# EG32M0x register map
Vendor: EGmicro Ltd.; Series: EG32M0x; File version: 1.0
CPU: CM0 r0p0, little endian, no MPU, no FPU, 3 interrupt priority bits
Registers are 32-bit, read-write, reset 0x0 unless marked. A register's access mark holds for its fields unless they carry their own. Offsets are from the block's base; [hi:lo] are bit positions; lines under a group give offsets from that group; {n}, {i} and the like mark numbered series; 'fields as' and 'values as' point back to an identical list.

## UART0 — UART0 unit
Base 0x40020290
Same registers: UART1 0x400202A0
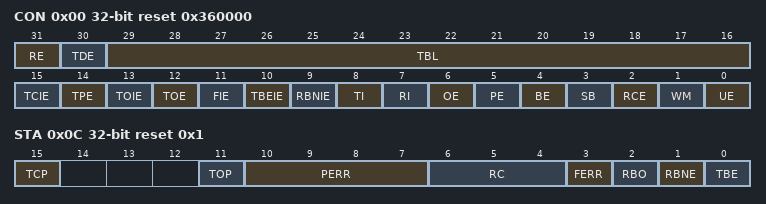
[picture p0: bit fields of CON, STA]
0x00 CON reset 0x360000
  [31] RE — DMA receive request enable configuration
  [30] TDE — DMA send request enable configuration
  [29:16] TBL — Timeout configuration
  [15] TCIE — The UART send completion interrupt was enabled
  [14] TPE — The TX of UART has TMR PWM carrier
  [13] TOIE — TIME OUT Indicates the interrupt enable bit
  [12] TOE — TIME OUT detects the enable bit
  [11] FIE — Frame error interrupt enable bit
  [10] TBEIE — Send buffer air break enable bit
  [9] RBNIE — Receive buffer non - air break enable bit
  [8] TI — Send the output signal to take the inverse selection bit
  [7] RI — Receive the input signal to take the inverse selection bit
  [6] OE — Parity check selection
  [5] PE — Parity check is enabled
  [4] BE — UART transmits 9bit data mode selection bits
  [3] SB — UART stop bit selection
  [2] RCE — Disable the UART receiving function
  [1] WM — UART working mode selection
  [0] UE — The UART module enabled bit
0x04 BAUD reset 0x9C3
  [17:0] BAUD — UART Baud rate control register
0x08 DATA
  [8:0] DATA — UART data register
0x0C STA reset 0x1
  [15] TCP — UART Send completion flag
  [11] TOP — TIME OUT flag bit
  [10:7] PERR — UART Parity check flag bit
  [6:4] RC — The number of cached data received by UART
  [3] FERR — Frame error
  [2] RBO — UART receive cache full flag
  [1] RBNE — Receive buffer non-empty flag
  [0] TBE — UART sends cache empty flag

## TIMER7 — TIMER7 unit
Base 0x40020310
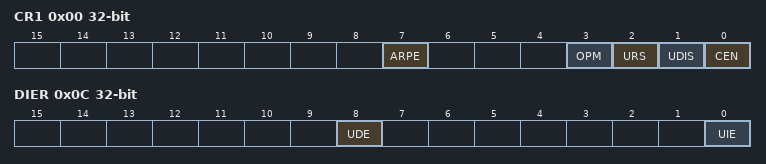
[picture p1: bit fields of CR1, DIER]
0x00 CR1
  [7] ARPE — Automatic reloading preloading allows bits
  [3] OPM — Single pulse mode
  [2] URS — Update request source
  [1] UDIS — Forbid updating
  [0] CEN — Enable counter
0x04 CR2
  [6:4] MMS — Master mode selection
0x0C DIER
  [8] UDE — DMA requests that allow updates
  [0] UIE — Allow update interrupt
0x10 SR
  [0] UIF — Update interrupt flag
0x14 EGR
  [0] UG — Generate update event
0x18 CNT
  [15:0] CNT — Counter value
0x1C PSC
  [15:0] PSC — The value of the pre-divider
0x20 ARR reset 0xFFFF
  [15:0] ARR — The value of automatic reloading

## ADC — ADC unit
Base 0x40020140
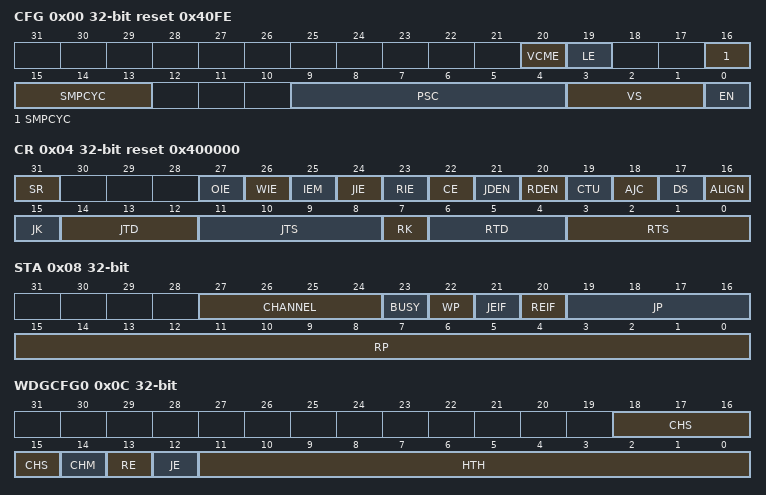
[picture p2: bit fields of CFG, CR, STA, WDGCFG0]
0x00 CFG reset 0x40FE
  [20] VCME — Enable VCM in ADC register
  [19] LE — Internal LDO of ADC module
  [16:13] SMPCYC — The interval between transitions
  [9:4] PSC — ADC predivision
  [3:1] VS — ADC reference voltage selection
  [0] EN — ADC enablement
0x04 CR reset 0x400000
  [31] SR — The software resets the internal state machine of the module
  [27] OIE — Overrun Interrupt enable bit
  [26] WIE — Threshold Watchdog interrupt enable bit
  [25] IEM — A/D interrupt mode bit
  [24] JIE — Injection channel A/D transition interrupt enable bit
  [23] RIE — Rule channel A/D transition interrupt enable bit
  [22] CE — Hardware data calibration enable bit
  [21] JDEN — Injection channel DMA enabled
  [20] RDEN — Enable regular channel DMA
  [19] CTU — Continuous conversion
  [18] AJC — Automatically starts the injection channel group conversion
  [17] DS — Data expansion bit selection
  [16] ALIGN — Data alignment
  [15] JK — The transformation of the injection channel begins
  [14:12] JTD — Delay sampling is triggered outside the injection channel
  [11:8] JTS — Trigger source selection for the injection channel
  [7] RK — The conversion of the regular channel begins
  [6:4] RTD — Delayed sampling is triggered externally by a regular channel
  [3:0] RTS — Trigger source selection for a rule channel
0x08 STA
  [27:24] CHANNEL — Current transfer channel
  [23] BUSY — Busy/idle flag
  [22] WP — Threshold watchdog flag bit
  [21] JEIF — Injection channel A/D conversion end flag bit
  [20] REIF — Rule channel A/D conversion end flag bit
  [19:16] JP — Injection channel conversion complete flag bit
  [15:0] RP — Regular channel conversion complete flag bit
0x0C WDGCFG0
  [18:15] CHS — Watchdog channel selector bit
  [14] CHM — Watchdog channel selection mode
  [13] RE — Turn on the watchdog in the regular aisle
  [12] JE — Enable watchdog on the injection channel
  [11:0] HTH — Watchdog high threshold
0x10 WDGCFG1
  [11:0] LTH — Watchdog low threshold
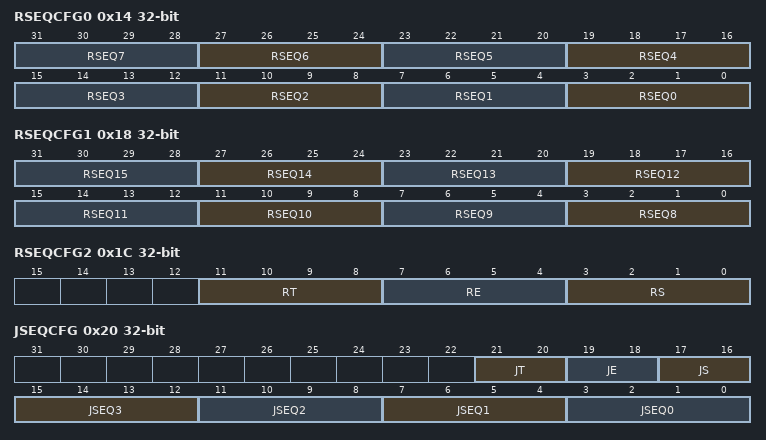
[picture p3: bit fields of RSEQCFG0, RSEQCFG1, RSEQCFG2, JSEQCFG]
0x14 RSEQCFG0
  [4n+3:4n] RSEQ{n} (n=0..7) — Channel configuration for rule sequence index {n}
0x18 RSEQCFG1
  [4n-29:4n-32] RSEQ{n} (n=8..15) — Channel configuration for rule sequence index {n}
0x1C RSEQCFG2
  [11:8] RT — Number of indexes for each conversion triggered by a rule sequence
  [7:4] RE — Regular sequence conversion ends index
  [3:0] RS — Regular sequence converts start index
0x20 JSEQCFG
  [21:20] JT — The number of indexes for each conversion triggered by the injection sequence
  [19:18] JE — The injection sequence converts the end index
  [17:16] JS — The injection sequence converts the star index
  [4n+3:4n] JSEQ{n} (n=0..3) — Channel configuration for injection sequence index {n}
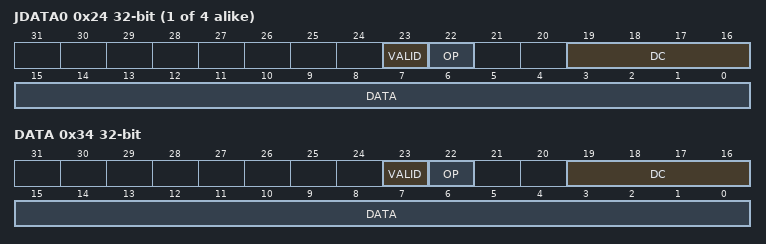
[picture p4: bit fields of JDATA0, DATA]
{0x24+4i} JDATA{i} (i=0..3)
  [23] VALID — DATA Indicates a valid flag bit
  [22] OP — Data override flag bit
  [19:16] DC — Displays the channel corresponding to the current data
  [15:0] DATA — 12-bit A/D conversion result
0x34 DATA
  fields as JDATA0
0x4C BUFCAL
  [7:0] BUFCAL — Simulates internal buffer offset calibration control
